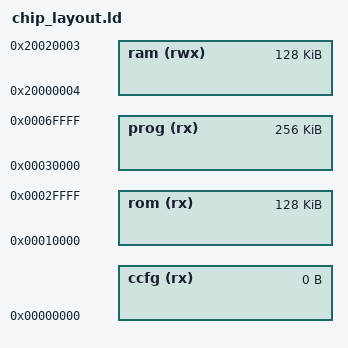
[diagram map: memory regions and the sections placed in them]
/* Memory Spaces Definitions, 448K flash, 64K ram */
ROM_ORIGIN  = 0x00010000; /* Use bootloader starting at 0x0000 */
ROM_LENGTH  = 0x00020000;
PROG_ORIGIN = 0x00030000;
PROG_LENGTH = 0x00040000;
RAM_ORIGIN  = 0x20000000;
RAM_LENGTH  = 0x00020000;

MPU_MIN_ALIGN = 8K;


MEMORY
{
  rom (rx)  : ORIGIN =  0x00010000, LENGTH =  0x00020000
  prog (rx) : ORIGIN = 0x00030000, LENGTH = 0x00040000
  ccfg (rx) : ORIGIN = 0, LENGTH = 0
  ram (rwx) : ORIGIN =  0x20000004, LENGTH =  0x00020000
}
